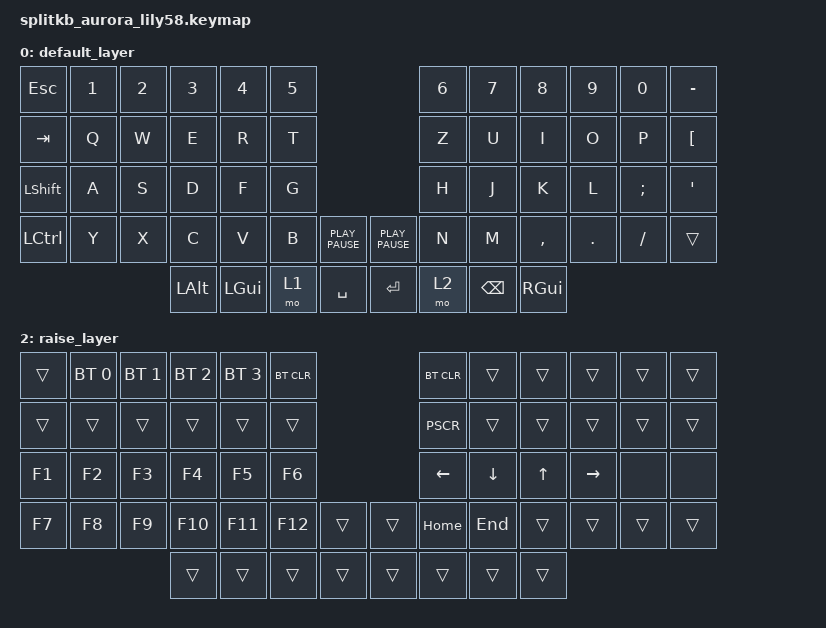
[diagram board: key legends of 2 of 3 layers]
/*
 * Copyright (c) 2022 The ZMK Contributors
 *
 * SPDX-License-Identifier: MIT
 */

#include <behaviors.dtsi>
#include <dt-bindings/zmk/keys.h>
#include <dt-bindings/zmk/bt.h>
#include <dt-bindings/zmk/ext_power.h>

/ {
    keymap {
        compatible = "zmk,keymap";

        default_layer {
// ------------------------------------------------------------------------------------------------------------
// |  ESC  |  1  |  2  |  3   |  4   |  5   |                   |  6   |  7    |  8    |  9   |   0   |   ß   |
// |  TAB  |  Q  |  W  |  E   |  R   |  T   |                   |  Y   |  U    |  I    |  O   |   P   |   Ü   |
// |  SHIFT |  A  |  S  |  D   |  F   |  G   |                   |  H   |  J    |  K    |  L   |   Ö   |   Ä   |
// |  CTRL |  Z  |  X  |  C   |  V   |  B   |  PLPA  |  |  PLPA |  N   |  M    |  ,    |  .   |   -   | SHIFT |
//                     | ALT  | GUI  | LOWER|  SPACE |  | ENTER | RAISE| BSPC  | GUI   |
            bindings = <
&kp ESC   &kp N1 &kp N2 &kp N3   &kp N4   &kp N5                                   &kp N6 &kp N7   &kp N8    &kp N9   &kp N0    &kp MINUS
&kp TAB   &kp Q  &kp W  &kp E    &kp R    &kp T                                    &kp Z  &kp U    &kp I     &kp O    &kp P     &kp LBKT
&kp LSHFT &kp A  &kp S  &kp D    &kp F    &kp G                                    &kp H  &kp J    &kp K     &kp L    &kp SEMI  &kp SQT
&kp LCTL  &kp Y  &kp X  &kp C    &kp V    &kp B  &kp K_PLAY_PAUSE &kp K_PLAY_PAUSE &kp N  &kp M    &kp COMMA &kp DOT  &kp FSLH  &trans
                        &kp LALT &kp LGUI &mo 1  &kp SPACE        &kp ENTER        &mo 2  &kp BSPC &kp RGUI
            >;

            sensor-bindings = <&inc_dec_kp C_VOL_UP C_VOL_DN>;
        };
  
          lower_layer {
  // ------------------------------------------------------------------------------------------------------------
  // | BTCLR | BT1 | BT2 |  BT3 |  BT4 |  BT5 |                   |      |       |       |      |       |       |
// |  F1   |  F2 |  F3 |  F4  |  F5  |  F6  |                   |  F7  |  F8   |  F9   |  F10 |  F11  |  F12  |
// |   `   |  !  |  @  |  #   |  $   |  %   |                   |  ^   |  &    |  *    |  (   |   )   |   ~   |
// |       |     |     |      |      |      |        |  |       |      |  _    |  +    |  {   |   }   |  "|"  |
//                     |      |      |      |        |  |       |      |       |       |
            bindings = <
&trans     &kp   F1     &kp F2    &kp F3     &kp F4 &kp F5                 &kp F6   &kp F7   &kp F8   &kp F9    &kp F10   &kp F11
&trans     &kp   RALT_Q &kp NUHS  &kp RALT_E &kp AT &lcurl                 &rcurl   &less    &kp AMPS &kp UNDER &kp GRAVE &kp F12
&kp GRAVE  &kp   CIRC   &kp GRAVE &dllr      &pipe  &kp ASTR               &kp LPAR &kp PEQL &bslsh   &kp EXCL  &kp RCBR  &kp TILDE
&trans     &none &none  &perc     &kp PLUS   &lcurl &trans   &trans &trans &rcurl   &grtr    &pipe    &kp PPLUS &tilde    &kp PIPE
                       &trans    &trans     &trans &trans   &trans &trans &kp DEL  &trans
            >;

            sensor-bindings = <&inc_dec_kp C_VOL_UP C_VOL_DN>;
        };

        raise_layer {
// -------------------------------------------------------------------------------------------------------------
// | BTCLR | BT1 | BT2 | BT3 | BT4 | BT5 |                   | BTCLR |       |       |      |       |       |
// |       |     |     |     |     |     |                   |       |       |       |      |       |       |
// |   F1  | F2  |  F3 | F4  | F5  | F6  |                   |       |   <-  |   v   |  ^   |  ->   |       |
// |   F7  | F8  |  F9 | F10 | F11 | F12 |        |  |       |   +   |   -   |   =   |  [   |   ]   |   \   |
//                     |     |     |     |        |  |       |       |       |       |
            bindings = <
&trans &bt BT_SEL 0 &bt BT_SEL 1 &bt BT_SEL 2 &bt BT_SEL 3 &bt BT_CLR               &bt BT_CLR &trans   &trans &trans    &trans &trans
&trans &trans       &trans       &trans       &trans       &trans                   &kp PSCR   &trans   &trans &trans    &trans &trans
&kp F1 &kp F2       &kp F3       &kp F4       &kp F5       &kp F6                   &kp LEFT   &kp DOWN &kp UP &kp RIGHT &none  &none
&kp F7 &kp F8       &kp F9       &kp F10      &kp F11      &kp F12    &trans &trans &kp HOME   &kp END  &trans &trans    &trans &trans
                                 &trans       &trans       &trans     &trans &trans &trans     &trans   &trans
            >;

            sensor-bindings = <&inc_dec_kp C_VOL_UP C_VOL_DN>;
        };
    };
    macros {
        lcurl: lcurl {
            compatible = "zmk,behavior-macro";
            #binding-cells = <0>;
            bindings = <&kp LEFT_BRACE>;
        };

        rcurl: rcurl {
            compatible = "zmk,behavior-macro";
            #binding-cells = <0>;
            bindings = <&kp RIGHT_BRACE>;
        };

        lbrck: lbrck {
            compatible = "zmk,behavior-macro";
            #binding-cells = <0>;
            bindings = <&kp LEFT_BRACKET>;
        };

        rbrck: rbrck {
            compatible = "zmk,behavior-macro";
            #binding-cells = <0>;
            bindings = <&kp RIGHT_BRACKET>;
        };

        pipe: pipe {
            compatible = "zmk,behavior-macro";
            #binding-cells = <0>;
            bindings = <&kp PIPE>;
        };

        bslsh: bslsh {
            compatible = "zmk,behavior-macro";
            #binding-cells = <0>;
            bindings = <&kp BACKSLASH>;
        };

        less: less {
            compatible = "zmk,behavior-macro";
            #binding-cells = <0>;
            bindings = <&kp LESS_THAN>;
        };

        grtr: grtr {
            compatible = "zmk,behavior-macro";
            #binding-cells = <0>;
            bindings = <&kp GREATER_THAN>;
        };

        eur: eur {
            compatible = "zmk,behavior-macro";
            #binding-cells = <0>;
            bindings = <&kp EURO>;
        };

        dllr: dllr {
            compatible = "zmk,behavior-macro";
            #binding-cells = <0>;
            bindings = <&kp DOLLAR>;
        };

        perc: perc {
            compatible = "zmk,behavior-macro";
            #binding-cells = <0>;
            bindings = <&kp PERCENT>;
        };

        tilde: tilde {
            compatible = "zmk,behavior-macro";
            #binding-cells = <0>;
            bindings = <&kp TILDE>;
        };
    };
};
